# STM32W108 register map
File version: 1.0
CPU: 
Registers are 32-bit, read-write, reset 0x0 unless marked. A register's access mark holds for its fields unless they carry their own. Offsets are from the block's base; [hi:lo] are bit positions; {n}, {i} and the like mark numbered series.

## RST — Reset event
Base 0x4000002C
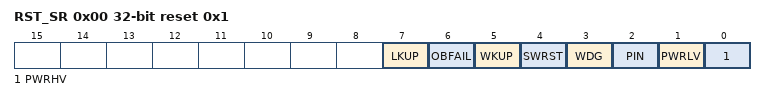
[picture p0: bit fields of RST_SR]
0x00 RST_SR ro reset 0x1 — Reset Status Register
  [7] LKUP, [6] OBFAIL, [5] WKUP, [4] SWRST, [3] WDG, [2] PIN, [1] PWRLV, [0] PWRHV

## FLASH
Base 0x4000402C
0x00 FLASH_CLKER — FLASH controller clock enable register
  [0] EN
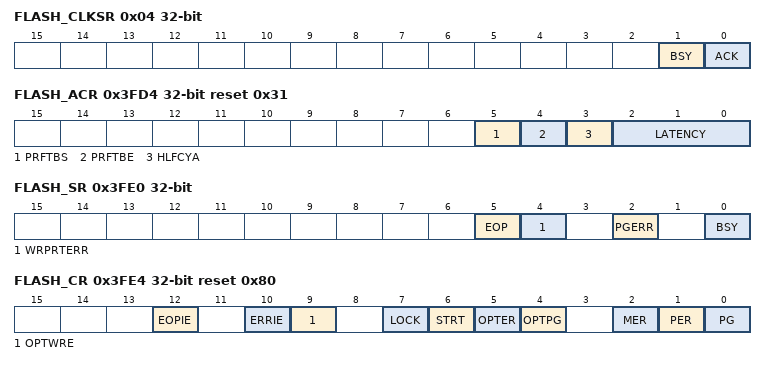
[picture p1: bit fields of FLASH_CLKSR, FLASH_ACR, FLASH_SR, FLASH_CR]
0x04 FLASH_CLKSR — FLASH controller clock status register
  [1] BSY, [0] ACK
0x3FD4 FLASH_ACR access per field reset 0x31 — FLASH access control register
  [5] PRFTBS ro — Prefetch Status
  [4] PRFTBE rw
  [3] HLFCYA rw
  [2:0] LATENCY rw
0x3FD8 FLASH_KEYR wo — FLASH key register
  [31:0] FKEYR
0x3FDC FLASH_OPTKEYR wo — FLASH OPT key register
0x3FE0 FLASH_SR access per field — FLASH status register
  [5] EOP rw, [4] WRPRTERR rw, [2] PGERR rw, [0] BSY wo
0x3FE4 FLASH_CR reset 0x80 — FLASH control register
  [12] EOPIE, [10] ERRIE, [9] OPTWRE, [7] LOCK, [6] STRT, [5] OPTER, [4] OPTPG, [2] MER, [1] PER, [0] PG
0x3FE8 FLASH_AR — FLASH address register
  [31:0] FAR
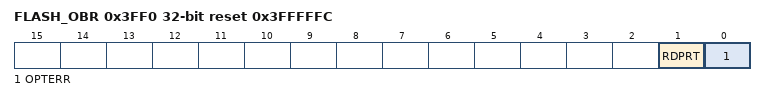
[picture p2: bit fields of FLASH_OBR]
0x3FF0 FLASH_OBR ro reset 0x3FFFFFC — FLASH option bytes register
  [1] RDPRT, [0] OPTERR
0x3FF4 FLASH_WRPR ro reset 0xFFFFFFFF — FLASH write protection register
  [31:0] WRP

## SLPTMR — Sleep timer
Base 0x4000600C
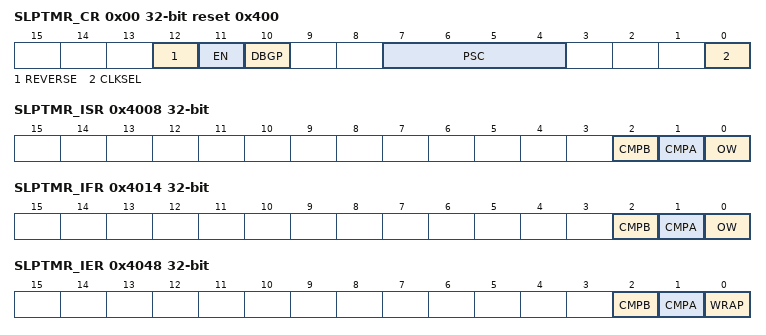
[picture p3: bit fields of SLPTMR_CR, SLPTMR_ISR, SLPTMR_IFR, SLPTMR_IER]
0x00 SLPTMR_CR reset 0x400 — SLPTMR configuration register
  [12] REVERSE, [11] EN, [10] DBGP, [7:4] PSC, [0] CLKSEL
0x04 SLPTMR_CNTH ro — SLPTMR counter high register
  [15:0] CNTH
0x08 SLPTMR_CNTL ro — SLPTMR counter high register
  [15:0] CNTL
0x0C SLPTMR_CMPAH reset 0xFFFF — SLPTMR compare A high register
  [15:0] CMPAH
0x10 SLPTMR_CMPAL reset 0xFFFF — SLPTMR compare A low register
  [15:0] CMPAL
0x14 SLPTMR_CMPBH reset 0xFFFF — SLPTMR compare B high register
  [15:0] CMPBH
0x18 SLPTMR_CMPBL reset 0xFFFF — SLPTMR compare B low register
  [15:0] CMPBL
0x4008 SLPTMR_ISR — SLPTMR interrupt status register
  [2] CMPB, [1] CMPA, [0] OW
0x4014 SLPTMR_IFR — SLPTMR force interrupts register
  [2] CMPB, [1] CMPA, [0] OW
0x4048 SLPTMR_IER — SLPTMR interrupt enable register
  [2] CMPB, [1] CMPA, [0] WRAP

## PWR — Power control
Base 0x40000004
0x00 PWR_DSLEEPCR1
  [1] PWR_CSYSPWRUPACKCR
0x10 PWR_DSLEEPCR2
  [0] MODE
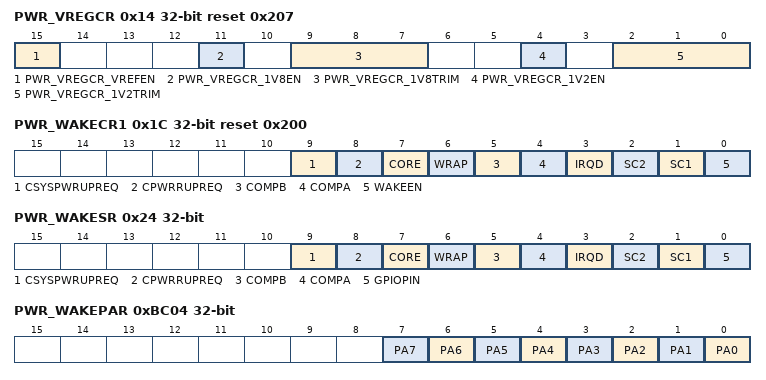
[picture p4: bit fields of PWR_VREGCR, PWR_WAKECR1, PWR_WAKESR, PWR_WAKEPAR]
0x14 PWR_VREGCR reset 0x207 — Voltage regulator Control register
  [15] PWR_VREGCR_VREFEN — VREF on/off
  [11] PWR_VREGCR_1V8EN — 1V8 direct controle of regulator on/off
  [9:7] PWR_VREGCR_1V8TRIM — 1V8 regulator trim value
  [4] PWR_VREGCR_1V2EN — 1V2 direct controle of regulator on/off
  [2:0] PWR_VREGCR_1V2TRIM — 1V2 regulator trim value
0x1C PWR_WAKECR1 reset 0x200
  [9] CSYSPWRUPREQ, [8] CPWRRUPREQ, [7] CORE, [6] WRAP, [5] COMPB, [4] COMPA, [3] IRQD, [2] SC2, [1] SC1, [0] WAKEEN
0x20 PWR_WAKECR2 wo
  [5] COREWAKE
0x24 PWR_WAKESR
  [9] CSYSPWRUPREQ, [8] CPWRRUPREQ, [7] CORE, [6] WRAP, [5] COMPB, [4] COMPA, [3] IRQD, [2] SC2, [1] SC1, [0] GPIOPIN
0x30 PWR_CPWRUPREQSR ro
  [0] REQ
0x34 PWR_CSYSPWRUPREQSR ro
  [0] REQ
0x38 PWR_CSYSPWRUPACKSR ro
  [0] ACK
0x3C PWR_CSYSPWRUPACKCR ro
  [0] INHIBIT
0xBC04 PWR_WAKEPAR — Wake GPIO Port A register
  [n] PA{n} (n=0..7)
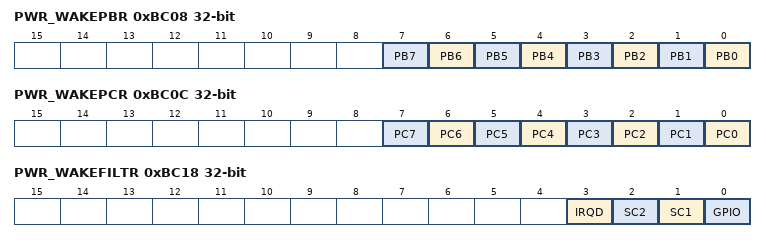
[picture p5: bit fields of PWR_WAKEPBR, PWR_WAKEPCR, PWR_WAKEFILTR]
0xBC08 PWR_WAKEPBR — Wake GPIO Port B register
  [n] PB{n} (n=0..7)
0xBC0C PWR_WAKEPCR — Wake GPIO Port C register
  [n] PC{n} (n=0..7)
0xBC18 PWR_WAKEFILTR — Wake filter register
  [3] IRQD — Enable filter on GPIO wakeup source EXTI D
  [2] SC2 — Enable filter on GPIO wakeup source SC2 (PA2)
  [1] SC1 — Enable filter on GPIO wakeup source SC1 (PB2)
  [0] GPIO — Enable filter on GPIO wakeup sources enabled by the PWR_WAKEPxR registers

## NVIC — Nested Vectored Interrupt Controller
Base 0xE000E000
0x04 ICTR ro — Interrupt Controller Type Register
  [3:0] INTLINESNUM — Total number of interrupt lines in groups
0x100 ISER0 — Interrupt Set-Enable Register
  [31:0] SETENA
0x180 ICER0 — Interrupt Clear-Enable Register
  [31:0] CLRENA
0x200 ISPR0 — Interrupt Set-Pending Register
  [31:0] SETPEND
0x280 ICPR0 — Interrupt Clear-Pending Register
  [31:0] CLRPEND
0x300 IABR0 ro — Interrupt Active Bit Register
  [31:0] ACTIVE
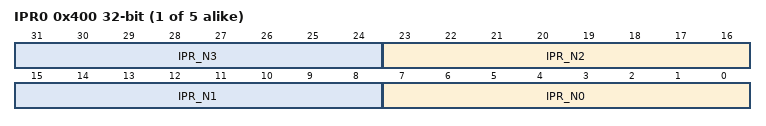
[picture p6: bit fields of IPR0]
{0x400+4i} IPR{i} (i=0..4) — Interrupt Priority Register
  [8n+7:8n] IPR_N{n} (n=0..3)
0xF00 STIR wo — Software Triggered Interrupt Register
  [8:0] INTID — interrupt to be triggered
